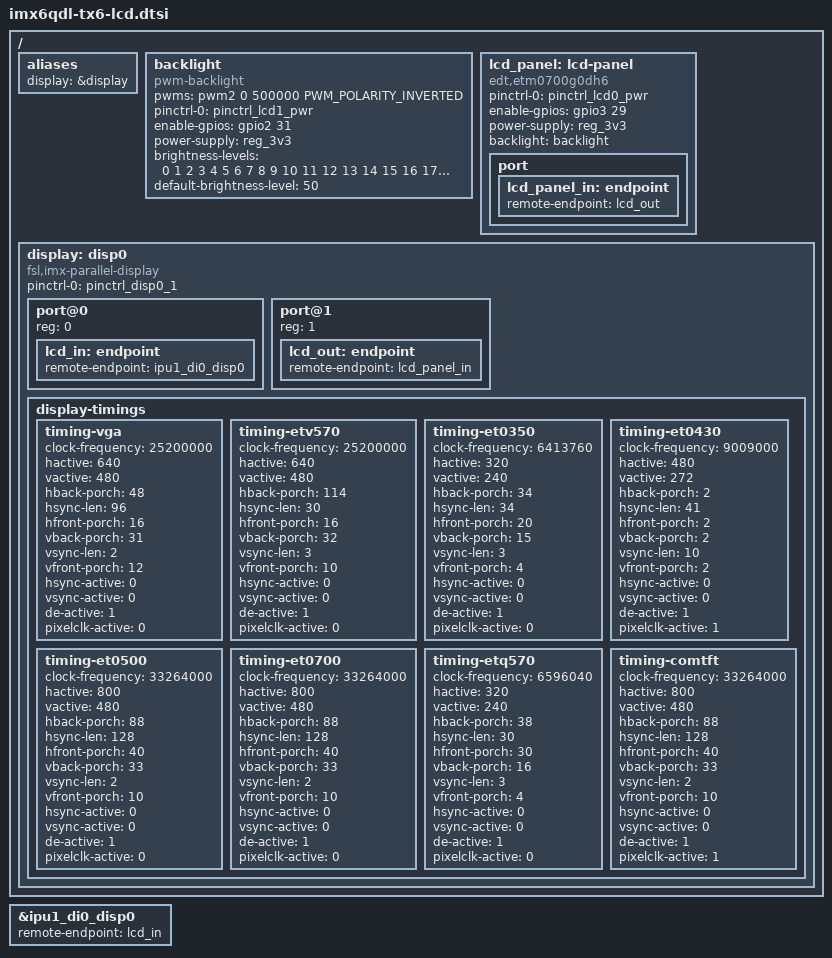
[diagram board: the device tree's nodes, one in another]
// SPDX-License-Identifier: (GPL-2.0-only OR MIT)
/*
 * Copyright 2017 Lothar Waßmann <LW@KARO-electronics.de>
 */

/ {
	aliases {
		display = &display;
	};

	backlight: backlight {
		compatible = "pwm-backlight";
		pwms = <&pwm2 0 500000 PWM_POLARITY_INVERTED>;
		pinctrl-names = "default";
		pinctrl-0 = <&pinctrl_lcd1_pwr>;
		enable-gpios = <&gpio2 31 GPIO_ACTIVE_HIGH>;
		power-supply = <&reg_3v3>;
		/*
		 * a poor man's way to create a 1:1 relationship between
		 * the PWM value and the actual duty cycle
		 */
		brightness-levels = < 0  1  2  3  4  5  6  7  8  9
				     10 11 12 13 14 15 16 17 18 19
				     20 21 22 23 24 25 26 27 28 29
				     30 31 32 33 34 35 36 37 38 39
				     40 41 42 43 44 45 46 47 48 49
				     50 51 52 53 54 55 56 57 58 59
				     60 61 62 63 64 65 66 67 68 69
				     70 71 72 73 74 75 76 77 78 79
				     80 81 82 83 84 85 86 87 88 89
				     90 91 92 93 94 95 96 97 98 99
				    100>;
		default-brightness-level = <50>;
	};

	lcd_panel: lcd-panel {
		compatible = "edt,etm0700g0dh6";
		pinctrl-names = "default";
		pinctrl-0 = <&pinctrl_lcd0_pwr>;
		enable-gpios = <&gpio3 29 GPIO_ACTIVE_HIGH>;
		power-supply = <&reg_3v3>;
		backlight = <&backlight>;

		port {
			lcd_panel_in: endpoint {
				remote-endpoint = <&lcd_out>;
			};
		};
	};

	display: disp0 {
		compatible = "fsl,imx-parallel-display";
		#address-cells = <1>;
		#size-cells = <0>;
		pinctrl-names = "default";
		pinctrl-0 = <&pinctrl_disp0_1>;
		status = "okay";

		port@0 {
			reg = <0>;

			lcd_in: endpoint {
				remote-endpoint = <&ipu1_di0_disp0>;
			};
		};

		port@1 {
			reg = <1>;

			lcd_out: endpoint {
				remote-endpoint = <&lcd_panel_in>;
			};
		};

		display-timings {
			timing-vga {
				clock-frequency = <25200000>;
				hactive = <640>;
				vactive = <480>;
				hback-porch = <48>;
				hsync-len = <96>;
				hfront-porch = <16>;
				vback-porch = <31>;
				vsync-len = <2>;
				vfront-porch = <12>;
				hsync-active = <0>;
				vsync-active = <0>;
				de-active = <1>;
				pixelclk-active = <0>;
			};

			timing-etv570 {
				clock-frequency = <25200000>;
				hactive = <640>;
				vactive = <480>;
				hback-porch = <114>;
				hsync-len = <30>;
				hfront-porch = <16>;
				vback-porch = <32>;
				vsync-len = <3>;
				vfront-porch = <10>;
				hsync-active = <0>;
				vsync-active = <0>;
				de-active = <1>;
				pixelclk-active = <0>;
			};

			timing-et0350 {
				clock-frequency = <6413760>;
				hactive = <320>;
				vactive = <240>;
				hback-porch = <34>;
				hsync-len = <34>;
				hfront-porch = <20>;
				vback-porch = <15>;
				vsync-len = <3>;
				vfront-porch = <4>;
				hsync-active = <0>;
				vsync-active = <0>;
				de-active = <1>;
				pixelclk-active = <0>;
			};

			timing-et0430 {
				clock-frequency = <9009000>;
				hactive = <480>;
				vactive = <272>;
				hback-porch = <2>;
				hsync-len = <41>;
				hfront-porch = <2>;
				vback-porch = <2>;
				vsync-len = <10>;
				vfront-porch = <2>;
				hsync-active = <0>;
				vsync-active = <0>;
				de-active = <1>;
				pixelclk-active = <1>;
			};

			timing-et0500 {
				clock-frequency = <33264000>;
				hactive = <800>;
				vactive = <480>;
				hback-porch = <88>;
				hsync-len = <128>;
				hfront-porch = <40>;
				vback-porch = <33>;
				vsync-len = <2>;
				vfront-porch = <10>;
				hsync-active = <0>;
				vsync-active = <0>;
				de-active = <1>;
				pixelclk-active = <0>;
			};

			timing-et0700 { /* same as ET0500 */
				clock-frequency = <33264000>;
				hactive = <800>;
				vactive = <480>;
				hback-porch = <88>;
				hsync-len = <128>;
				hfront-porch = <40>;
				vback-porch = <33>;
				vsync-len = <2>;
				vfront-porch = <10>;
				hsync-active = <0>;
				vsync-active = <0>;
				de-active = <1>;
				pixelclk-active = <0>;
			};

			timing-etq570 {
				clock-frequency = <6596040>;
				hactive = <320>;
				vactive = <240>;
				hback-porch = <38>;
				hsync-len = <30>;
				hfront-porch = <30>;
				vback-porch = <16>;
				vsync-len = <3>;
				vfront-porch = <4>;
				hsync-active = <0>;
				vsync-active = <0>;
				de-active = <1>;
				pixelclk-active = <0>;
			};

			timing-comtft { /* same as ET0700 but with inverted pixel clock */
				clock-frequency = <33264000>;
				hactive = <800>;
				vactive = <480>;
				hback-porch = <88>;
				hsync-len = <128>;
				hfront-porch = <40>;
				vback-porch = <33>;
				vsync-len = <2>;
				vfront-porch = <10>;
				hsync-active = <0>;
				vsync-active = <0>;
				de-active = <1>;
				pixelclk-active = <1>;
			};
		};
	};
};

&ipu1_di0_disp0 {
	remote-endpoint = <&lcd_in>;
};
